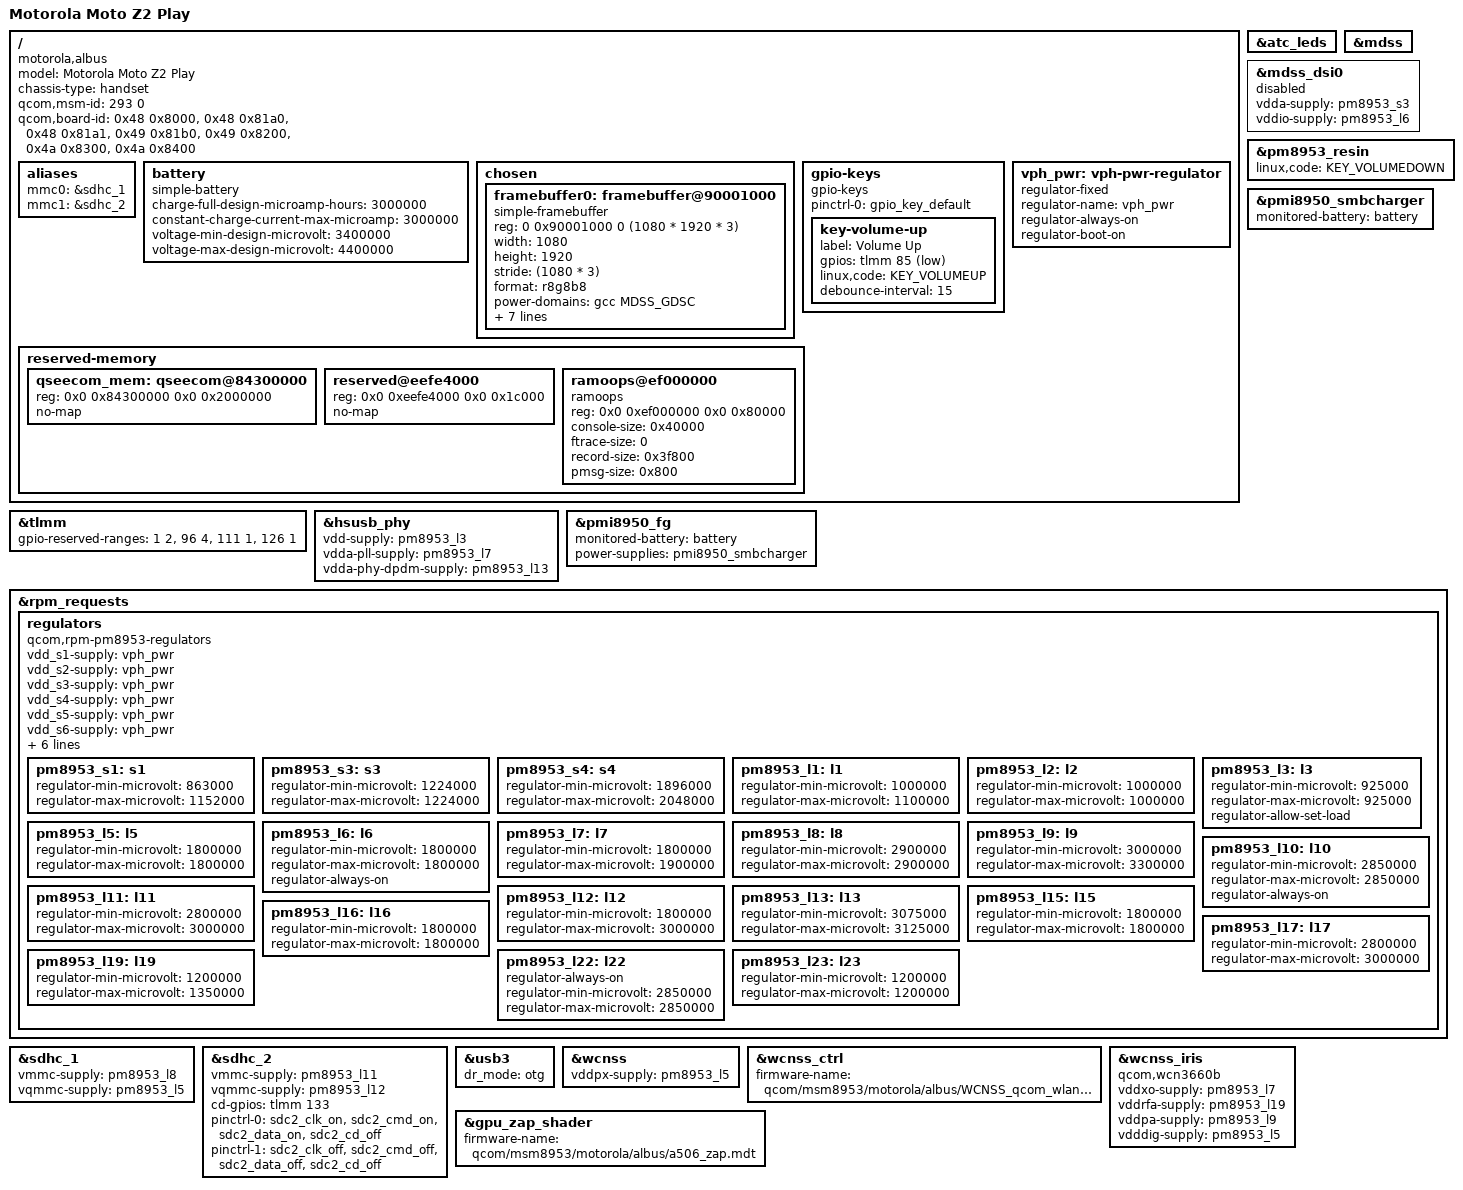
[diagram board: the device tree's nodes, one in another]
// SPDX-License-Identifier: BSD-3-Clause
/*
 * Copyright (c) 2026, SaaS <hearesaas@gmail.com>
 *
 * Motorola Moto Z2 Play (albus) - Qualcomm MSM8953-Pro.
 */

/dts-v1/;

#include "msm8953.dtsi"
#include "pm8953.dtsi"
#include "pmi8950.dtsi"

/delete-node/ &cont_splash_mem;
/delete-node/ &qseecom_mem;

/ {
	model = "Motorola Moto Z2 Play";
	compatible = "motorola,albus", "qcom,msm8953";
	chassis-type = "handset";

	qcom,msm-id = <293 0>;
	qcom,board-id = <0x48 0x8000>, <0x48 0x81a0>,
			<0x48 0x81a1>, <0x49 0x81b0>,
			<0x49 0x8200>, <0x4a 0x8300>,
			<0x4a 0x8400>;

	aliases {
		mmc0 = &sdhc_1;
		mmc1 = &sdhc_2;
	};

	battery: battery {
		compatible = "simple-battery";

		charge-full-design-microamp-hours = <3000000>;
		constant-charge-current-max-microamp = <3000000>;
		voltage-min-design-microvolt = <3400000>;
		voltage-max-design-microvolt = <4400000>;
	};

	chosen {
		#address-cells = <2>;
		#size-cells = <2>;
		ranges;

		framebuffer0: framebuffer@90001000 {
			compatible = "simple-framebuffer";
			reg = <0 0x90001000 0 (1080 * 1920 * 3)>;

			width = <1080>;
			height = <1920>;
			stride = <(1080 * 3)>;
			format = "r8g8b8";

			power-domains = <&gcc MDSS_GDSC>;

			clocks = <&gcc GCC_MDSS_AHB_CLK>,
				 <&gcc GCC_MDSS_AXI_CLK>,
				 <&gcc GCC_MDSS_VSYNC_CLK>,
				 <&gcc GCC_MDSS_MDP_CLK>,
				 <&gcc GCC_MDSS_BYTE0_CLK>,
				 <&gcc GCC_MDSS_PCLK0_CLK>,
				 <&gcc GCC_MDSS_ESC0_CLK>;
		};
	};

	gpio-keys {
		compatible = "gpio-keys";

		pinctrl-names = "default";
		pinctrl-0 = <&gpio_key_default>;

		key-volume-up {
			label = "Volume Up";
			gpios = <&tlmm 85 GPIO_ACTIVE_LOW>;
			linux,code = <KEY_VOLUMEUP>;
			debounce-interval = <15>;
		};
	};

	reserved-memory {
		qseecom_mem: qseecom@84300000 {
			reg = <0x0 0x84300000 0x0 0x2000000>;
			no-map;
		};

		reserved@eefe4000 {
			reg = <0x0 0xeefe4000 0x0 0x1c000>;
			no-map;
		};

		ramoops@ef000000 {
			compatible = "ramoops";
			reg = <0x0 0xef000000 0x0 0x80000>;
			console-size = <0x40000>;
			ftrace-size = <0>;
			record-size = <0x3f800>;
			pmsg-size = <0x800>;
		};
	};

	vph_pwr: vph-pwr-regulator {
		compatible = "regulator-fixed";
		regulator-name = "vph_pwr";
		regulator-always-on;
		regulator-boot-on;
	};
};

/* The TZ-claimed GPIO ranges match the stock "qcom,tz_gpio" list. */
&tlmm {
	gpio-reserved-ranges = <1 2>, <96 4>, <111 1>, <126 1>;
};

&atc_leds {
	status = "okay";
};

&hsusb_phy {
	vdd-supply = <&pm8953_l3>;
	vdda-pll-supply = <&pm8953_l7>;
	vdda-phy-dpdm-supply = <&pm8953_l13>;

	status = "okay";
};

&mdss {
	status = "okay";
};

/* The Samsung SMD549-ALB 1080p command-mode AMOLED panel needs a generated
 * mainline panel driver first; until then the framebuffer is handed over
 * from the bootloader and the DSI host stays disabled. */
&mdss_dsi0 {
	vdda-supply = <&pm8953_s3>;
	vddio-supply = <&pm8953_l6>;

	status = "disabled";
};

&pm8953_resin {
	linux,code = <KEY_VOLUMEDOWN>;
	status = "okay";
};

&pmi8950_fg {
	monitored-battery = <&battery>;
	power-supplies = <&pmi8950_smbcharger>;
	status = "okay";
};

&pmi8950_smbcharger {
	monitored-battery = <&battery>;
	status = "okay";
};

&rpm_requests {
	regulators {
		compatible = "qcom,rpm-pm8953-regulators";
		vdd_s1-supply = <&vph_pwr>;
		vdd_s2-supply = <&vph_pwr>;
		vdd_s3-supply = <&vph_pwr>;
		vdd_s4-supply = <&vph_pwr>;
		vdd_s5-supply = <&vph_pwr>;
		vdd_s6-supply = <&vph_pwr>;
		vdd_s7-supply = <&vph_pwr>;
		vdd_l1-supply = <&pm8953_s3>;
		vdd_l2_l3-supply = <&pm8953_s3>;
		vdd_l4_l5_l6_l7_l16_l19-supply = <&pm8953_s4>;
		vdd_l8_l11_l12_l13_l14_l15-supply = <&vph_pwr>;
		vdd_l9_l10_l17_l18_l22-supply = <&vph_pwr>;

		pm8953_s1: s1 {
			regulator-min-microvolt = <863000>;
			regulator-max-microvolt = <1152000>;
		};

		pm8953_s3: s3 {
			regulator-min-microvolt = <1224000>;
			regulator-max-microvolt = <1224000>;
		};

		pm8953_s4: s4 {
			regulator-min-microvolt = <1896000>;
			regulator-max-microvolt = <2048000>;
		};

		pm8953_l1: l1 {
			regulator-min-microvolt = <1000000>;
			regulator-max-microvolt = <1100000>;
		};

		pm8953_l2: l2 {
			regulator-min-microvolt = <1000000>;
			regulator-max-microvolt = <1000000>;
		};

		pm8953_l3: l3 {
			regulator-min-microvolt = <925000>;
			regulator-max-microvolt = <925000>;
			regulator-allow-set-load;
		};

		pm8953_l5: l5 {
			regulator-min-microvolt = <1800000>;
			regulator-max-microvolt = <1800000>;
		};

		pm8953_l6: l6 {
			regulator-min-microvolt = <1800000>;
			regulator-max-microvolt = <1800000>;
			regulator-always-on;
		};

		pm8953_l7: l7 {
			regulator-min-microvolt = <1800000>;
			regulator-max-microvolt = <1900000>;
		};

		pm8953_l8: l8 {
			regulator-min-microvolt = <2900000>;
			regulator-max-microvolt = <2900000>;
		};

		pm8953_l9: l9 {
			regulator-min-microvolt = <3000000>;
			regulator-max-microvolt = <3300000>;
		};

		pm8953_l10: l10 {
			regulator-min-microvolt = <2850000>;
			regulator-max-microvolt = <2850000>;
			regulator-always-on;
		};

		pm8953_l11: l11 {
			regulator-min-microvolt = <2800000>;
			regulator-max-microvolt = <3000000>;
		};

		pm8953_l12: l12 {
			regulator-min-microvolt = <1800000>;
			regulator-max-microvolt = <3000000>;
		};

		pm8953_l13: l13 {
			regulator-min-microvolt = <3075000>;
			regulator-max-microvolt = <3125000>;
		};

		pm8953_l15: l15 {
			regulator-min-microvolt = <1800000>;
			regulator-max-microvolt = <1800000>;
		};

		pm8953_l16: l16 {
			regulator-min-microvolt = <1800000>;
			regulator-max-microvolt = <1800000>;
		};

		pm8953_l17: l17 {
			regulator-min-microvolt = <2800000>;
			regulator-max-microvolt = <3000000>;
		};

		pm8953_l19: l19 {
			regulator-min-microvolt = <1200000>;
			regulator-max-microvolt = <1350000>;
		};

		/* The stock device tree pins l22 at 2.85 V (motorola ep4). */
		pm8953_l22: l22 {
			regulator-always-on;
			regulator-min-microvolt = <2850000>;
			regulator-max-microvolt = <2850000>;
		};

		pm8953_l23: l23 {
			regulator-min-microvolt = <1200000>;
			regulator-max-microvolt = <1200000>;
		};
	};
};

&sdhc_1 {
	vmmc-supply = <&pm8953_l8>;
	vqmmc-supply = <&pm8953_l5>;

	status = "okay";
};

&sdhc_2 {
	vmmc-supply = <&pm8953_l11>;
	vqmmc-supply = <&pm8953_l12>;

	/* Card-detect line and pinctrl states match the stock device tree. */
	cd-gpios = <&tlmm 133 GPIO_ACTIVE_HIGH>;

	pinctrl-names = "default", "sleep";
	pinctrl-0 = <&sdc2_clk_on &sdc2_cmd_on &sdc2_data_on &sdc2_cd_off>;
	pinctrl-1 = <&sdc2_clk_off &sdc2_cmd_off &sdc2_data_off &sdc2_cd_off>;

	status = "okay";
};

&usb3 {
	/* USB Type-C port; the DWC3 role switch defaults to peripheral mode
	 * (as configured by the SoC dtsi) until a Type-C controller node is
	 * added.  The RNDIS gadget is the current lifeline of this device. */
	dr_mode = "otg";
	status = "okay";
};

&wcnss {
	vddpx-supply = <&pm8953_l5>;

	status = "okay";
};

&wcnss_ctrl {
	firmware-name = "qcom/msm8953/motorola/albus/WCNSS_qcom_wlan_nv.bin";
};

&wcnss_iris {
	compatible = "qcom,wcn3660b";

	vddxo-supply = <&pm8953_l7>;
	vddrfa-supply = <&pm8953_l19>;
	vddpa-supply = <&pm8953_l9>;
	vdddig-supply = <&pm8953_l5>;
};

&gpu_zap_shader {
	firmware-name = "qcom/msm8953/motorola/albus/a506_zap.mdt";
};

/* The modem (mpss) remoteproc driver requires a "firmware-name" property
 * which msm8953.dtsi does not define yet; enable it once that lands. */
